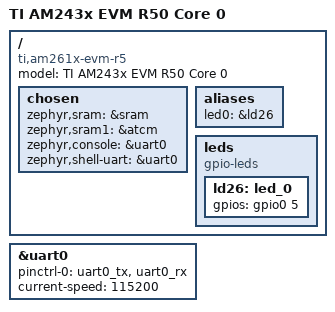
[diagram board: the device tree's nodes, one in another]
/* Copyright (c) 2025 Texas Instruments Incorporated
 *
 * SPDX-License-Identifier: Apache-2.0
 */

/dts-v1/;

#include <zephyr/dt-bindings/gpio/gpio.h>
#include <ti/am64x_r5.dtsi>
#include "am261x_evm_am261x_r5f0_0-pinctrl.dtsi"

/ {
	model = "TI AM243x EVM R50 Core 0";
	compatible = "ti,am261x-evm-r5";

	chosen {
		zephyr,sram = &sram;
		zephyr,sram1 = &atcm;
		zephyr,console = &uart0;
		zephyr,shell-uart = &uart0;
	};

	aliases {
		led0 = &ld26;  //check the number
	};

	leds: leds {
		compatible = "gpio-leds";

		ld26: led_0 {
			gpios = <&gpio0 5 GPIO_ACTIVE_HIGH>; //check gpio
		};
	};
};

/* system timer */
//might have to use RTI here
/*
&timer8 {
	status = "okay";
};
*/
&uart0 {
	status = "okay";
	pinctrl-0 = <&uart0_tx &uart0_rx>;
	pinctrl-names = "default";
	current-speed = <115200>;
};

/*
&mcu_gpio0 {
	pinctrl-0 = <&mcu_gpio0_led>;
	pinctrl-names = "default";
	status = "okay";
};

&i2c0 {
	pinctrl-0 = <&i2c0_scl &i2c0_sda>;
	pinctrl-names = "default";
	status = "okay";
};

&mbox6 {
	usr-id = <0>;
	status = "okay";
};
*/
